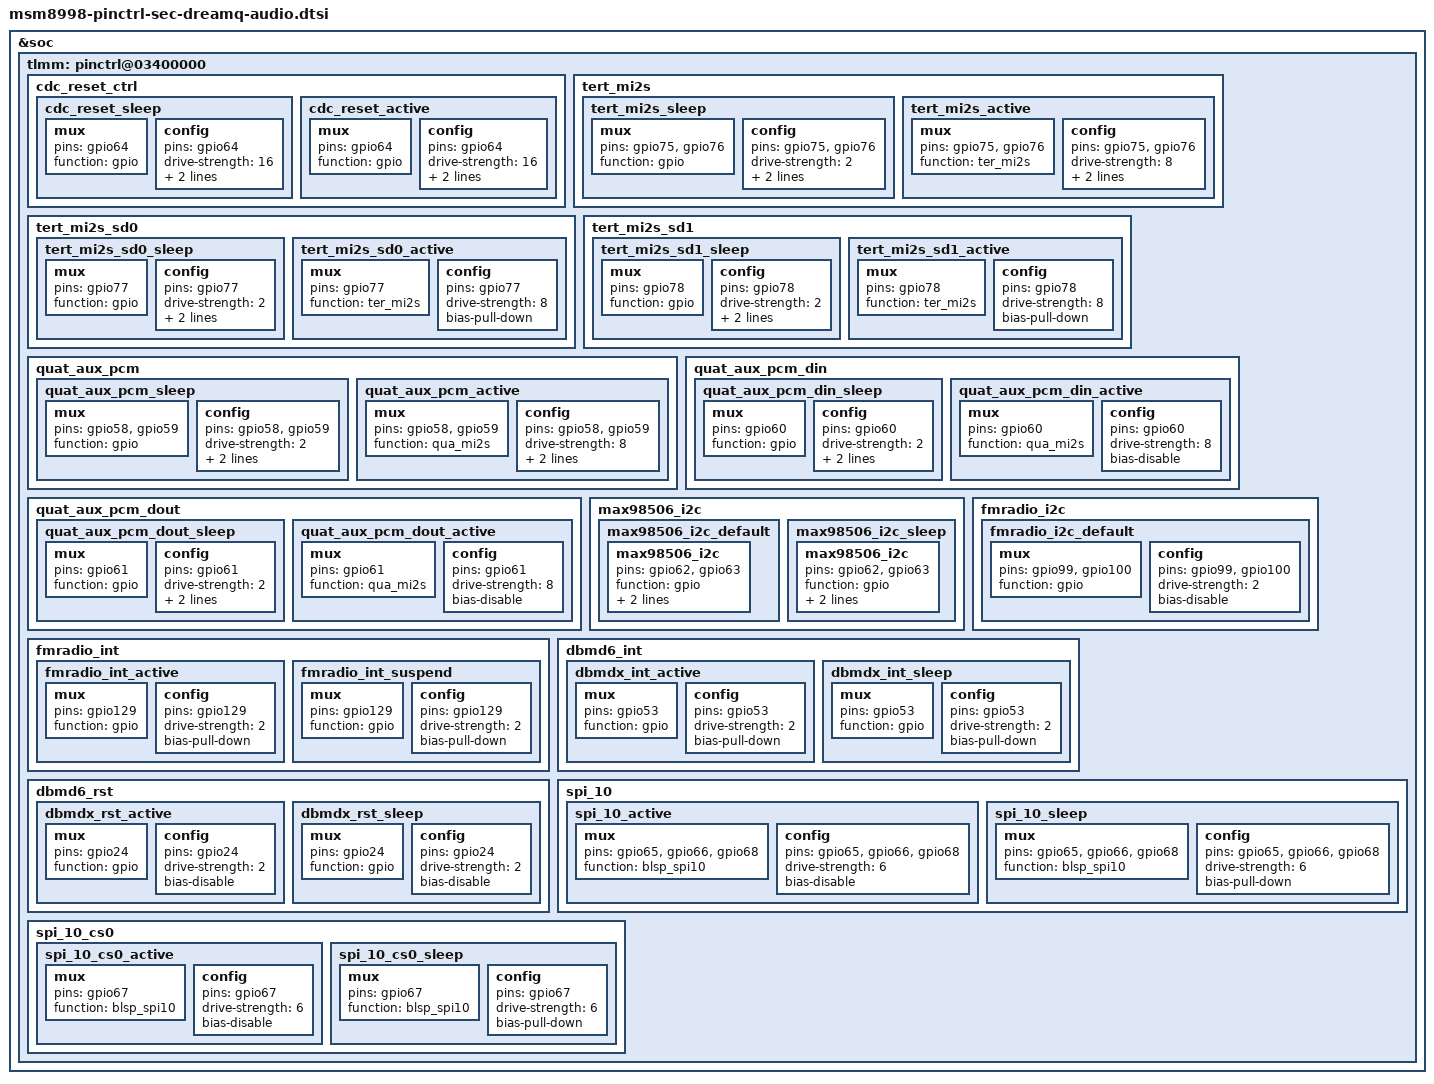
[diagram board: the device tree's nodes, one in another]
/* Copyright (c) 2015-2016, The Linux Foundation. All rights reserved.
 *
 * This program is free software; you can redistribute it and/or modify
 * it under the terms of the GNU General Public License version 2 and
 * only version 2 as published by the Free Software Foundation.
 *
 * This program is distributed in the hope that it will be useful,
 * but WITHOUT ANY WARRANTY; without even the implied warranty of
 * MERCHANTABILITY or FITNESS FOR A PARTICULAR PURPOSE.  See the
 * GNU General Public License for more details.
 */

&soc {
	tlmm: pinctrl@03400000 {
		/delete-node/wcd_gnd_mic_swap;
		/delete-node/spkr_1_sd_n;
		/delete-node/spkr_2_sd_n;

		/delete-node/cdc_reset_ctrl;
		cdc_reset_ctrl {
			cdc_reset_sleep: cdc_reset_sleep {
				mux {
					pins = "gpio64";
					function = "gpio";
				};
				config {
					pins = "gpio64";
					drive-strength = <16>;
					bias-disable;
					output-low;
				};
			};
			cdc_reset_active:cdc_reset_active {
				mux {
					pins = "gpio64";
					function = "gpio";
				};
				config {
					pins = "gpio64";
					drive-strength = <16>;
					bias-disable;
					output-high;
				};
			};
		};

		tert_mi2s {
			tert_mi2s_sleep: tert_mi2s_sleep {
				mux {
					pins = "gpio75", "gpio76";
					function = "gpio";
				};

				config {
					pins = "gpio75", "gpio76";
					drive-strength = <2>;   /* 2 mA */
					bias-pull-down;         /* PULL DOWN */
					input-enable;
				};
			};
			tert_mi2s_active: tert_mi2s_active {
				mux {
					pins = "gpio75", "gpio76";
					function = "ter_mi2s";
				};

				config {
					pins = "gpio75", "gpio76";
					drive-strength = <8>;   /* 8 mA */
					bias-disable;           /* NO PULL */
					output-high;
				};
			};
		};

		tert_mi2s_sd0 {
			tert_mi2s_sd0_sleep: tert_mi2s_sd0_sleep {
				mux {
					pins = "gpio77";
					function = "gpio";
				};

				config {
					pins = "gpio77";
					drive-strength = <2>;   /* 2 mA */
					bias-pull-down;         /* PULL DOWN */
					input-enable;
				};
			};
			tert_mi2s_sd0_active: tert_mi2s_sd0_active {
				mux {
					pins = "gpio77";
					function = "ter_mi2s";
				};

				config {
					pins = "gpio77";
					drive-strength = <8>;   /* 8 mA */
					bias-pull-down;         /* PULL DOWN */
				};
			};
		};

		tert_mi2s_sd1 {
			tert_mi2s_sd1_sleep: tert_mi2s_sd1_sleep {
				mux {
					pins = "gpio78";
					function = "gpio";
				};

				config {
					pins = "gpio78";
					drive-strength = <2>;   /* 2 mA */
					bias-pull-down;         /* PULL DOWN */
					input-enable;
				};
			};
			tert_mi2s_sd1_active: tert_mi2s_sd1_active {
				mux {
					pins = "gpio78";
					function = "ter_mi2s";
				};

				config {
					pins = "gpio78";
					drive-strength = <8>;   /* 8 mA */
					bias-pull-down;         /* PULL DOWN */
				};
			};
		};

		quat_aux_pcm {
			quat_aux_pcm_sleep: quat_aux_pcm_sleep {
				mux {
					pins = "gpio58", "gpio59";
					function = "gpio";
				};

				config {
					pins = "gpio58", "gpio59";
					drive-strength = <2>;   /* 2 mA */
					bias-pull-down;         /* PULL DOWN */
					input-enable;
				};
			};

			quat_aux_pcm_active: quat_aux_pcm_active {
				mux {
					pins = "gpio58", "gpio59";
					function = "qua_mi2s";
				};

				config {
					pins = "gpio58", "gpio59";
					drive-strength = <8>;   /* 8 mA */
					bias-disable;           /* NO PULL */
					output-high;
				};
			};
		};

		quat_aux_pcm_din {
			quat_aux_pcm_din_sleep: quat_aux_pcm_din_sleep {
				mux {
					pins = "gpio60";
					function = "gpio";
				};

				config {
					pins = "gpio60";
					drive-strength = <2>;   /* 2 mA */
					bias-pull-down;         /* PULL DOWN */
					input-enable;
				};
			};

			quat_aux_pcm_din_active: quat_aux_pcm_din_active {
				mux {
					pins = "gpio60";
					function = "qua_mi2s";
				};

				config {
					pins = "gpio60";
					drive-strength = <8>;   /* 8 mA */
					bias-disable;           /* NO PULL */
				};
			};
		};

		quat_aux_pcm_dout {
			quat_aux_pcm_dout_sleep: quat_aux_pcm_dout_sleep {
				mux {
					pins = "gpio61";
					function = "gpio";
				};

				config {
					pins = "gpio61";
					drive-strength = <2>;   /* 2 mA */
					bias-pull-down;         /* PULL DOWN */
					input-enable;
				};
			};

			quat_aux_pcm_dout_active: quat_aux_pcm_dout_active {
				mux {
					pins = "gpio61";
					function = "qua_mi2s";
				};

				config {
					pins = "gpio61";
					drive-strength = <8>;   /* 8 mA */
					bias-disable;           /* NO PULL */
				};
			};
		};

		max98506_i2c {
			max98506_i2c_default: max98506_i2c_default {
				max98506_i2c {
					pins = "gpio62", "gpio63";
					function = "gpio";
					drive-strength = <2>;
					bias-disable;
				};
			};
			max98506_i2c_sleep: max98506_i2c_sleep {
				max98506_i2c {
					pins = "gpio62", "gpio63";
					function = "gpio";
					drive-strength = <2>;
					bias-disable;
				};
			};
		};

		fmradio_i2c {
			fmradio_i2c_default: fmradio_i2c_default {
				mux {
					pins = "gpio99", "gpio100";
					function = "gpio";
				};
				config {
					pins = "gpio99", "gpio100";
					drive-strength = <2>; /* 2 MA */
					bias-disable; /* No PULL */
				};
			};
		};		

		fmradio_int {
			fmradio_int_active: fmradio_int_active {
				mux {
					pins = "gpio129";
					function = "gpio";
				};
				config {
					pins = "gpio129";
					drive-strength = <2>; /* 2 MA */
					bias-pull-down; /* PULL DOWN */
				};
			};

			fmradio_int_suspend: fmradio_int_suspend {
				mux {
					pins = "gpio129";
					function = "gpio";
				};
				config {
					pins = "gpio129";
					drive-strength = <2>; /* 2 MA */
					bias-pull-down; /* PULL DOWN */
				};
			};
		};

		dbmd6_int {
			dbmdx_int_active: dbmdx_int_active {
				mux {
					pins = "gpio53";
					function = "gpio";
				};			
				config {
					pins = "gpio53";
					drive-strength = <2>;
					bias-pull-down;
				};
			};

			dbmdx_int_sleep: dbmdx_int_sleep {
				mux {
					pins = "gpio53";
					function = "gpio";
				};			
				config {
					pins = "gpio53";
					drive-strength = <2>;
					bias-pull-down;
				};
			};
		};
		
		dbmd6_rst {
			dbmdx_rst_active: dbmdx_rst_active {
				mux {
					pins = "gpio24";
					function = "gpio";
				};			
				config {
					pins = "gpio24";
					drive-strength = <2>;
					bias-disable;
				};
			};

			dbmdx_rst_sleep: dbmdx_rst_sleep {
				mux {
					pins = "gpio24";
					function = "gpio";
				};			
				config {
					pins = "gpio24";
					drive-strength = <2>;
					bias-disable;
				};
			};
		};

		spi_10 {
			spi_10_active: spi_10_active {
				mux {
					pins = "gpio65", "gpio66", "gpio68";
					function = "blsp_spi10";
				};

				config {
					pins = "gpio65", "gpio66", "gpio68";
					drive-strength = <6>;
					bias-disable;
				};
			};

			spi_10_sleep: spi_10_sleep {
				mux {
					pins = "gpio65", "gpio66", "gpio68";
					function = "blsp_spi10";
				};

				config {
					pins = "gpio65", "gpio66", "gpio68";
					drive-strength = <6>;
					bias-pull-down;
					
				};
			};
		};
		
		spi_10_cs0 {
			/* CS0 */
			spi_10_cs0_active: spi_10_cs0_active {
				mux {
					pins = "gpio67";
					function = "blsp_spi10";
				};
				config {
					pins = "gpio67";
					drive-strength = <6>;
					bias-disable;
				};
			};

			spi_10_cs0_sleep: spi_10_cs0_sleep {
				mux {
					pins = "gpio67";
					function = "blsp_spi10";
				};
				config {
					pins = "gpio67";
					drive-strength = <6>;
					bias-pull-down;
				};
			};
		};
	};
};
